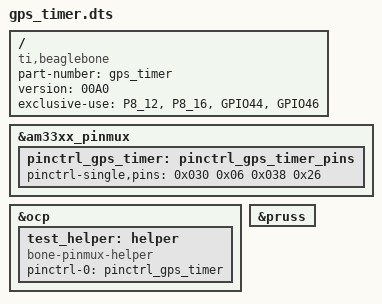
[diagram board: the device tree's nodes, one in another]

/dts-v1/;
/plugin/;

/ {
  compatible = "ti,beaglebone", "ti,beaglebone-black";

  /* identification */
  part-number = "gps_timer";
  version = "00A0";

  exclusive-use =
    "P8_12", "P8_16",
    "GPIO44", "GPIO46";

  fragment@0 {
    target = <&am33xx_pinmux>;
    __overlay__ {
    pinctrl_gps_timer: pinctrl_gps_timer_pins {
        pinctrl-single,pins = <
					/*
						Table of mux options:
						Bit 0 \
						Bit 1 |- Mode
						Bit 2 /
						Bit 3: 1 - Pull disabled, 0 - Pull enabled
						
						Bit 4: 1 - Pull up, 0 - Pull down
						Bit 5: 1 - Input, 0 – Output
					*/
					0x030 0x06 /* P8_12 gpio1[12] GPIO44 output pulldown Mode: 6 */
					0x038 0x26 /* P8_16 gpio1[14] GPIO46 input pulldown Mode: 6 */
					// 0x07c 0x07 /* P8_26 gpio1[29] GPIO61 output pulldown Mode: 7 */
          >;
      };
    };
  };

  fragment@1 {
    target = <&ocp>;
    __overlay__ {
      test_helper: helper {
        compatible = "bone-pinmux-helper";
        pinctrl-names = "default";
        pinctrl-0 = <&pinctrl_gps_timer>;
        status = "okay";
      };
    };
  };

  fragment@2{
  target = <&pruss>;
    __overlay__ {
      status = "okay";
    };
  };
};
